# earlgrey register map
Vendor: lowRISC; File version: snapshot-20191101-1-539-gaf065293
CPU: other 0, little endian, no MPU, no FPU, 0 interrupt priority bits
Registers are 32-bit, read-write, reset 0x0 unless marked. A register's access mark holds for its fields unless they carry their own. Offsets are from the block's base; [hi:lo] are bit positions; lines under a group give offsets from that group; {n}, {i} and the like mark numbered series.

## alert_handler
Base 0x40130000
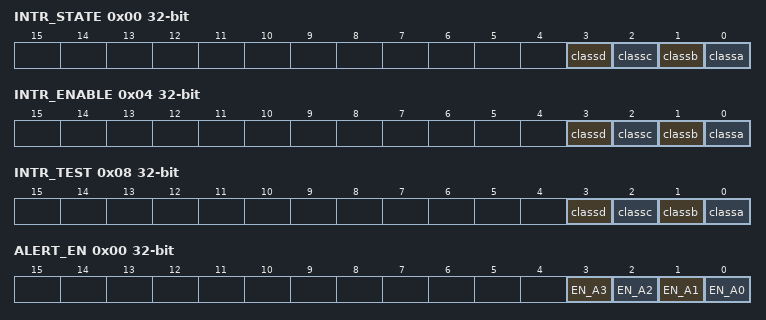
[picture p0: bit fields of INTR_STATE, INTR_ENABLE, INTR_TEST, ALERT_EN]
0x00 INTR_STATE — Interrupt State Register
  [3] classd write-1-clears — Interrupt state bit of Class D. Set by HW in case an alert within this class triggered. Defaults true, write one to clear.
  [2] classc write-1-clears — Interrupt state bit of Class C. Set by HW in case an alert within this class triggered. Defaults true, write one to clear.
  [1] classb write-1-clears — Interrupt state bit of Class B. Set by HW in case an alert within this class triggered. Defaults true, write one to clear.
  [0] classa write-1-clears — Interrupt state bit of Class A. Set by HW in case an alert within this class triggered. Defaults true, write one to clear.
0x04 INTR_ENABLE — Interrupt Enable Register
  [3] classd — Enable interrupt when !!INTR_STATE.classd is set
  [2] classc — Enable interrupt when !!INTR_STATE.classc is set
  [1] classb — Enable interrupt when !!INTR_STATE.classb is set
  [0] classa — Enable interrupt when !!INTR_STATE.classa is set
0x08 INTR_TEST wo — Interrupt Test Register
  [3] classd — Write 1 to force !!INTR_STATE.classd to 1
  [2] classc — Write 1 to force !!INTR_STATE.classc to 1
  [1] classb — Write 1 to force !!INTR_STATE.classb to 1
  [0] classa — Write 1 to force !!INTR_STATE.classa to 1
0x0C REGEN 1-bit reset 0x1 write-1-clears — Register write enable for all control registers.
0x10 PING_TIMEOUT_CYC 24-bit reset 0x20 — Ping timeout cycle count.
0x14 ALERT_EN group — Enable register for alerts.
  0x00 ALERT_EN — Enable register for alerts.
    [3] EN_A3 — for alert3
    [2] EN_A2 — for alert2
    [1] EN_A1 — for alert1
    [0] EN_A0 — Alert enable for alert0
0x18 ALERT_CLASS group — Class assignment of alerts.
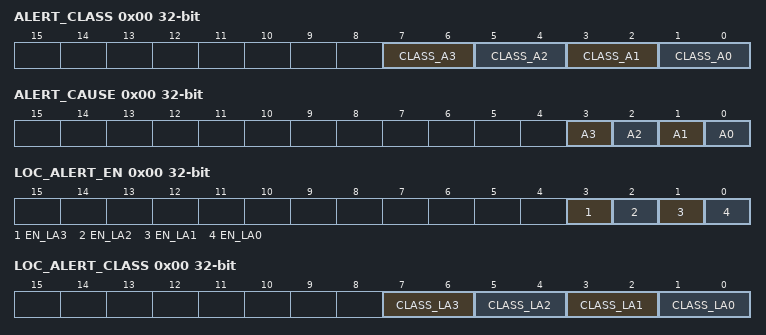
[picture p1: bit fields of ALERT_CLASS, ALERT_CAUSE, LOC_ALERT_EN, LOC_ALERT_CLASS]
  0x00 ALERT_CLASS — Class assignment of alerts.
    [7:6] CLASS_A3 — for alert3
    [5:4] CLASS_A2 — for alert2
    [3:2] CLASS_A1 — for alert1
    [1:0] CLASS_A0 — Classification for alert0
0x1C ALERT_CAUSE group
  0x00 ALERT_CAUSE write-1-clears
    [3] A3 write-1-clears — for ALERT3
    [2] A2 write-1-clears — for ALERT2
    [1] A1 write-1-clears — for ALERT1
    [0] A0 write-1-clears — Cause bit for ALERT0
0x20 LOC_ALERT_EN group — Enable register for the aggregated local alerts "alert pingfail" (0), "escalation pingfail" (1), "alert integfail" (2) and "escalation integfail" (3).
  0x00 LOC_ALERT_EN — Enable register for the aggregated local alerts "alert pingfail" (0), "escalation pingfail" (1), "alert integfail" (2) and "escalation integfail" (3).
    [3] EN_LA3 — for local alert3
    [2] EN_LA2 — for local alert2
    [1] EN_LA1 — for local alert1
    [0] EN_LA0 — Alert enable for local alert0
0x24 LOC_ALERT_CLASS group — Class assignment of local alerts. "alert pingfail" (0), "escalation pingfail" (1), "alert integfail" (2) and "escalation integfail" (3).
  0x00 LOC_ALERT_CLASS — Class assignment of local alerts. "alert pingfail" (0), "escalation pingfail" (1), "alert integfail" (2) and "escalation integfail" (3).
    [7:6] CLASS_LA3 — for local alert3
    [5:4] CLASS_LA2 — for local alert2
    [3:2] CLASS_LA1 — for local alert1
    [1:0] CLASS_LA0 — Classification for local alert0
0x28 LOC_ALERT_CAUSE group — Alert Cause Register for Local Alerts. "alert pingfail" (0), "escalation pingfail" (1), "alert integfail" (2) and "escalation integfail" (3).
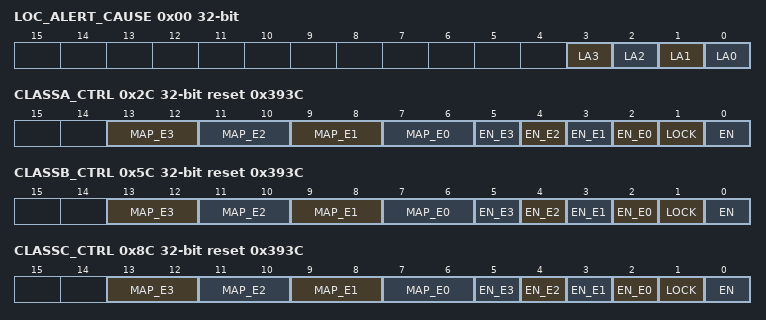
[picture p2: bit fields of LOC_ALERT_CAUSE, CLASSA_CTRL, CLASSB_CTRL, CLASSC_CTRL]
  0x00 LOC_ALERT_CAUSE write-1-clears — Alert Cause Register for Local Alerts. "alert pingfail" (0), "escalation pingfail" (1), "alert integfail" (2) and "escalation integfail" (3).
    [3] LA3 write-1-clears — for LOC_ALERT3
    [2] LA2 write-1-clears — for LOC_ALERT2
    [1] LA1 write-1-clears — for LOC_ALERT1
    [0] LA0 write-1-clears — Cause bit for LOC_ALERT0
0x2C CLASSA_CTRL reset 0x393C — Escalation control register for alert Class A. Can not be modified if !!REGEN is false.
  [13:12] MAP_E3 — Determines in which escalation phase escalation signal 3 shall be asserted.
  [11:10] MAP_E2 — Determine sin which escalation phase escalation signal 2 shall be asserted.
  [9:8] MAP_E1 — Determines in which escalation phase escalation signal 1 shall be asserted.
  [7:6] MAP_E0 — Determines in which escalation phase escalation signal 0 shall be asserted.
  [n+2] EN_E{n} (n=0..3) — Enable escalation signal {n} for Class A
  [1] LOCK — Enable automatic locking of escalation counter for class A. If true, there is no way to stop the escalation protocol for class A once it has been triggered.
  [0] EN — Enable escalation mechanisms (accumulation and interrupt timeout) for Class A. Note that interrupts can fire regardless of whether the escalation mechanisms are enabled for this class or not.
0x30 CLASSA_CLREN 1-bit reset 0x1 write-1-clears — Clear enable for escalation protocol of Class A alerts.
0x34 CLASSA_CLR 1-bit wo reset not defined — Clear for esclation protocol of Class A.
0x38 CLASSA_ACCUM_CNT 16-bit ro — Current accumulation value for alert Class A. Software can clear this register with a write to !!CLASSA_CLR register unless !!CLASSA_CLREN is false.
0x3C CLASSA_ACCUM_THRESH 16-bit — Accumulation threshold value for alert Class A.
0x40 CLASSA_TIMEOUT_CYC — Interrupt timeout in cycles.
{0x44+4i} CLASSA_PHASE{i}_CYC (i=0..3) — Duration of escalation phase {i} for Class A.
0x54 CLASSA_ESC_CNT ro — Escalation counter in cycles for Class A.
0x58 CLASSA_STATE 3-bit ro — Current escalation state of Class A. See also !!CLASSA_ESC_CNT.
0x5C CLASSB_CTRL reset 0x393C — Escalation control register for alert Class B. Can not be modified if !!REGEN is false.
  [13:12] MAP_E3 — Determines in which escalation phase escalation signal 3 shall be asserted.
  [11:10] MAP_E2 — Determine sin which escalation phase escalation signal 2 shall be asserted.
  [9:8] MAP_E1 — Determines in which escalation phase escalation signal 1 shall be asserted.
  [7:6] MAP_E0 — Determines in which escalation phase escalation signal 0 shall be asserted.
  [n+2] EN_E{n} (n=0..3) — Enable escalation signal {n} for Class B
  [1] LOCK — Enable automatic locking of escalation counter for class B. If true, there is no way to stop the escalation protocol for class B once it has been triggered.
  [0] EN — Enable escalation mechanisms (accumulation and interrupt timeout) for Class B. Note that interrupts can fire regardless of whether the escalation mechanisms are enabled for this class or not.
0x60 CLASSB_CLREN 1-bit reset 0x1 write-1-clears — Clear enable for escalation protocol of Class B alerts.
0x64 CLASSB_CLR 1-bit wo reset not defined — Clear for esclation protocol of Class B.
0x68 CLASSB_ACCUM_CNT 16-bit ro — Current accumulation value for alert Class B. Software can clear this register with a write to !!CLASSB_CLR register unless !!CLASSB_CLREN is false.
0x6C CLASSB_ACCUM_THRESH 16-bit — Accumulation threshold value for alert Class B.
0x70 CLASSB_TIMEOUT_CYC — Interrupt timeout in cycles.
{0x74+4i} CLASSB_PHASE{i}_CYC (i=0..3) — Duration of escalation phase {i} for Class B.
0x84 CLASSB_ESC_CNT ro — Escalation counter in cycles for Class B.
0x88 CLASSB_STATE 3-bit ro — Current escalation state of Class B. See also !!CLASSB_ESC_CNT.
0x8C CLASSC_CTRL reset 0x393C — Escalation control register for alert Class C. Can not be modified if !!REGEN is false.
  [13:12] MAP_E3 — Determines in which escalation phase escalation signal 3 shall be asserted.
  [11:10] MAP_E2 — Determine sin which escalation phase escalation signal 2 shall be asserted.
  [9:8] MAP_E1 — Determines in which escalation phase escalation signal 1 shall be asserted.
  [7:6] MAP_E0 — Determines in which escalation phase escalation signal 0 shall be asserted.
  [n+2] EN_E{n} (n=0..3) — Enable escalation signal {n} for Class C
  [1] LOCK — Enable automatic locking of escalation counter for class C. If true, there is no way to stop the escalation protocol for class C once it has been triggered.
  [0] EN — Enable escalation mechanisms (accumulation and interrupt timeout) for Class C. Note that interrupts can fire regardless of whether the escalation mechanisms are enabled for this class or not.
0x90 CLASSC_CLREN 1-bit reset 0x1 write-1-clears — Clear enable for escalation protocol of Class C alerts.
0x94 CLASSC_CLR 1-bit wo reset not defined — Clear for esclation protocol of Class C.
0x98 CLASSC_ACCUM_CNT 16-bit ro — Current accumulation value for alert Class C. Software can clear this register with a write to !!CLASSC_CLR register unless !!CLASSC_CLREN is false.
0x9C CLASSC_ACCUM_THRESH 16-bit — Accumulation threshold value for alert Class C.
0xA0 CLASSC_TIMEOUT_CYC — Interrupt timeout in cycles.
{0xA4+4i} CLASSC_PHASE{i}_CYC (i=0..3) — Duration of escalation phase {i} for Class C.
0xB4 CLASSC_ESC_CNT ro — Escalation counter in cycles for Class C.
0xB8 CLASSC_STATE 3-bit ro — Current escalation state of Class C. See also !!CLASSC_ESC_CNT.
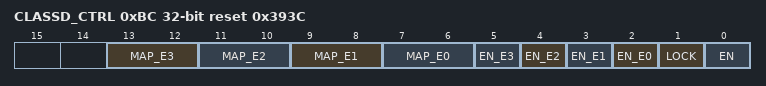
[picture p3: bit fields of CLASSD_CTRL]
0xBC CLASSD_CTRL reset 0x393C — Escalation control register for alert Class D. Can not be modified if !!REGEN is false.
  [13:12] MAP_E3 — Determines in which escalation phase escalation signal 3 shall be asserted.
  [11:10] MAP_E2 — Determine sin which escalation phase escalation signal 2 shall be asserted.
  [9:8] MAP_E1 — Determines in which escalation phase escalation signal 1 shall be asserted.
  [7:6] MAP_E0 — Determines in which escalation phase escalation signal 0 shall be asserted.
  [n+2] EN_E{n} (n=0..3) — Enable escalation signal {n} for Class D
  [1] LOCK — Enable automatic locking of escalation counter for class D. If true, there is no way to stop the escalation protocol for class D once it has been triggered.
  [0] EN — Enable escalation mechanisms (accumulation and interrupt timeout) for Class D. Note that interrupts can fire regardless of whether the escalation mechanisms are enabled for this class or not.
0xC0 CLASSD_CLREN 1-bit reset 0x1 write-1-clears — Clear enable for escalation protocol of Class D alerts.
0xC4 CLASSD_CLR 1-bit wo reset not defined — Clear for esclation protocol of Class D.
0xC8 CLASSD_ACCUM_CNT 16-bit ro — Current accumulation value for alert Class D. Software can clear this register with a write to !!CLASSD_CLR register unless !!CLASSD_CLREN is false.
0xCC CLASSD_ACCUM_THRESH 16-bit — Accumulation threshold value for alert Class D.
0xD0 CLASSD_TIMEOUT_CYC — Interrupt timeout in cycles.
{0xD4+4i} CLASSD_PHASE{i}_CYC (i=0..3) — Duration of escalation phase {i} for Class D.
0xE4 CLASSD_ESC_CNT ro — Escalation counter in cycles for Class D.
0xE8 CLASSD_STATE 3-bit ro — Current escalation state of Class D. See also !!CLASSD_ESC_CNT.
